# wut_reva_me18 register map
Registers are read-write, no defined reset value unless marked. A register's access mark holds for its fields unless they carry their own. Offsets are from the block's base; lines under a group give offsets from that group; [hi:lo] are bit positions; {n}, {i} and the like mark numbered series; 'fields as' and 'values as' point back to an identical list; <NAME> marks a mode.

## Memory map
0x40006400 WUT size 0x400 — Wake Up Timer

## Interrupts
53 WUT

## WUT — Wake Up Timer
Base 0x40006400
0x00 CNT — Wakeup Timer Count Register
  [15:0] COUNT — Timer Count Value.
0x04 CMP — Wakeup Timer Compare Register
  [31:0] COMPARE — Timer Compare Value.
0x0C INTFL — Wakeup Timer Interrupt Register
  [0] IRQ_CLR — Timer Interrupt.
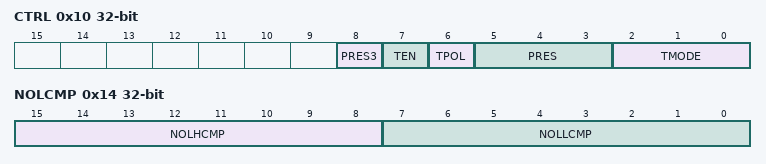
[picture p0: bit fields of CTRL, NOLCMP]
0x10 CTRL — Wakeup Timer Control Register
  [8] PRES3 — Timer Prescaler Select.
    0=pres3_1; 0=pres3_2; 0=pres3_4; 0=pres3_8; 0=pres3_16; 0=pres3_32; 0=pres3_64; 0=pres3_128; 1=pres3_256; 1=pres3_512; 1=pres3_1024; 1=pres3_2048; 1=pres3_4096
  [7] TEN — Timer Enable.
    0=timer_dis; 1=timer_en
  [6] TPOL — Timer Polarity.
  [5:3] PRES — Timer Prescaler Select.
    0=DIV1; 1=DIV2; 2=DIV4; 3=DIV8; 4=DIV16; 5=DIV32; 6=DIV64; 7=DIV128; 0=DIV256; 2=DIV512; 3=DIV1024; 4=DIV2048; 5=DIV4096
  [2:0] TMODE — Timer Mode Select.
    0=One Shot Mode; 1=Continuous Mode; 2=Counter Mode; 3=pwm (PWM Mode.); 4=Capture Mode; 5=Compare Mode; 6=Gated Mode; 7=Capture/Compare Mode
0x14 NOLCMP — Non Overlaping Compare Register
  [15:8] NOLHCMP — Non Overlaping High Compare.
  [7:0] NOLLCMP — Non Overlaping Low Compare.
0x18 PRESET access not given
  [31:0] PRESET — Preset Value.
0x1C RELOAD access not given
  [31:0] RELOAD — Reload Value.
0x20 SNAPSHOT access not given
  [31:0] SNAPSHOT — Snapshot Value.
